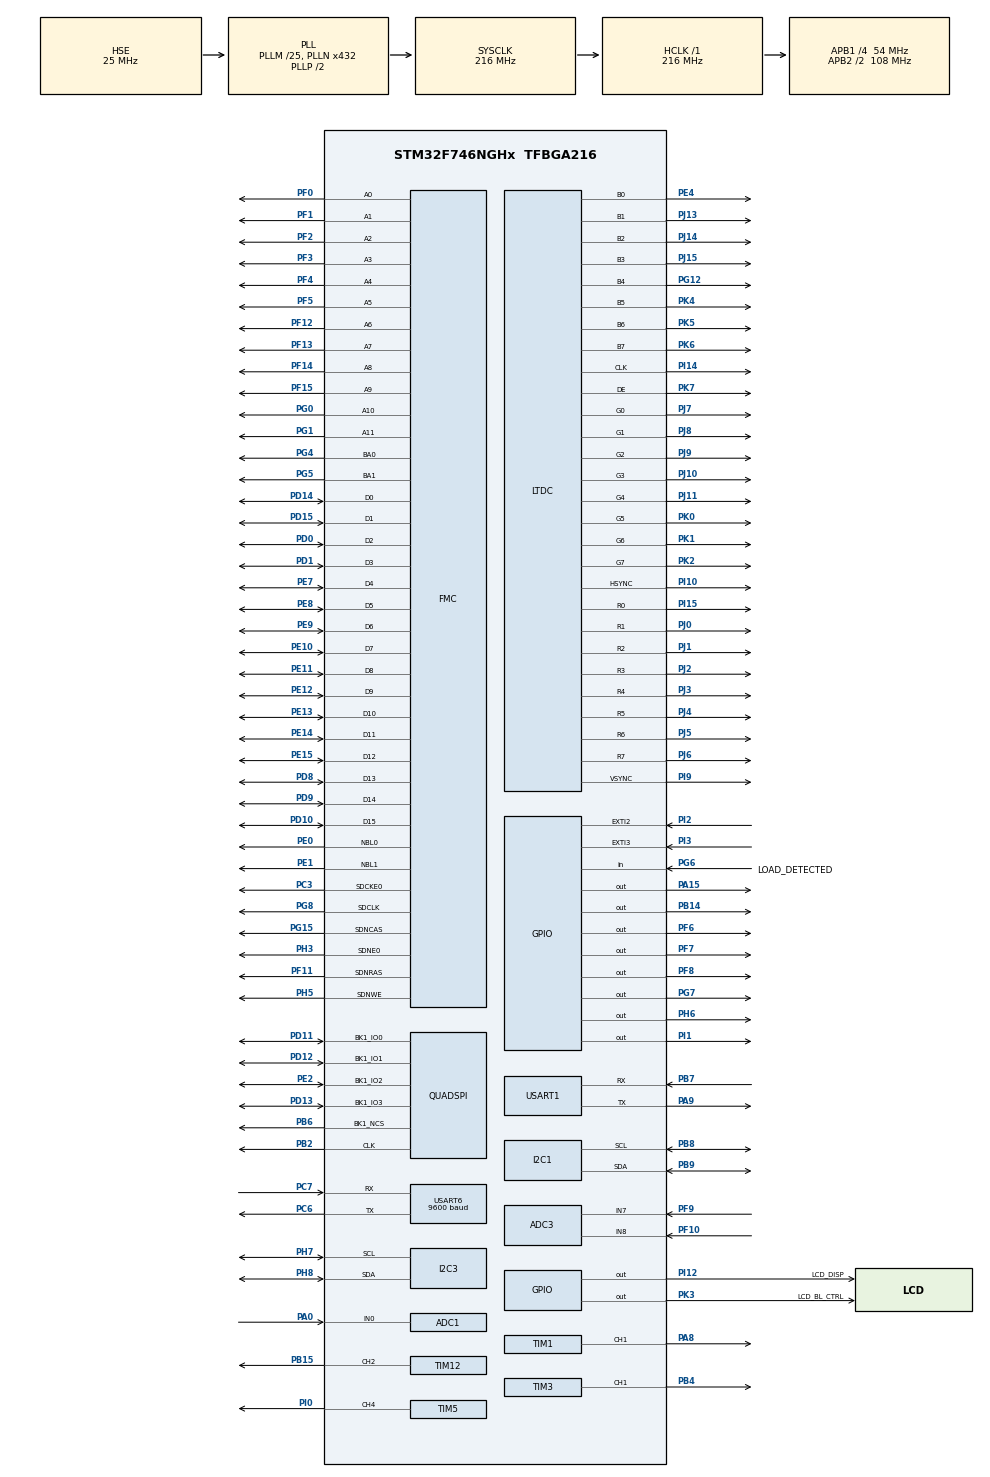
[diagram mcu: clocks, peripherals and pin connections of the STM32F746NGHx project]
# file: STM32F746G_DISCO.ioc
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ADC1.Channel-0\#ChannelRegularConversion=ADC_CHANNEL_0
ADC1.NbrOfConversionFlag=1
ADC1.Rank-0\#ChannelRegularConversion=1
ADC1.SamplingTime-0\#ChannelRegularConversion=ADC_SAMPLETIME_480CYCLES
ADC1.master=1
ADC3.Channel-0\#ChannelRegularConversion=ADC_CHANNEL_8
ADC3.NbrOfConversionFlag=1
ADC3.Rank-0\#ChannelRegularConversion=1
ADC3.SamplingTime-0\#ChannelRegularConversion=ADC_SAMPLETIME_480CYCLES
CORTEX_M7.ART_ACCLERATOR_ENABLE=1
CORTEX_M7.AccessPermission-Cortex_Memory_Protection_Unit_Region0_Settings=MPU_REGION_FULL_ACCESS
CORTEX_M7.AccessPermission-Cortex_Memory_Protection_Unit_Region1_Settings=MPU_REGION_FULL_ACCESS
CORTEX_M7.BaseAddress-Cortex_Memory_Protection_Unit_Region0_Settings=0x90000000
CORTEX_M7.BaseAddress-Cortex_Memory_Protection_Unit_Region1_Settings=0x90000000
CORTEX_M7.CPU_DCache=Enabled
CORTEX_M7.CPU_ICache=Enabled
CORTEX_M7.Enable-Cortex_Memory_Protection_Unit_Region0_Settings=MPU_REGION_ENABLE
CORTEX_M7.Enable-Cortex_Memory_Protection_Unit_Region1_Settings=MPU_REGION_ENABLE
CORTEX_M7.IsCacheable-Cortex_Memory_Protection_Unit_Region1_Settings=MPU_ACCESS_CACHEABLE
CORTEX_M7.MPU_Control=MPU_PRIVILEGED_DEFAULT
CORTEX_M7.PREFETCH_ENABLE=1
CORTEX_M7.Size-Cortex_Memory_Protection_Unit_Region0_Settings=MPU_REGION_SIZE_256MB
CORTEX_M7.Size-Cortex_Memory_Protection_Unit_Region1_Settings=MPU_REGION_SIZE_16MB
FMC.CASLatency1=FMC_SDRAM_CAS_LATENCY_3
FMC.ExitSelfRefreshDelay1=7
FMC.LoadToActiveDelay1=2
FMC.RCDDelay1=2
FMC.RPDelay1=2
FMC.ReadBurst1=FMC_SDRAM_RBURST_ENABLE
FMC.RowCycleDelay1=7
FMC.SDClockPeriod1=FMC_SDRAM_CLOCK_PERIOD_2
FMC.SelfRefreshTime1=4
FMC.WriteRecoveryTime1=3
FREERTOS.Tasks01=defaultTask,40,128,StartDefaultTask,Default,NULL,Dynamic,NULL,NULL;TouchGFXTask,24,4096,TouchGFX_Task,As external,NULL,Dynamic,NULL,NULL;videoTask,8,1000,videoTaskFunc,As external,NULL,Dynamic,NULL,NULL
FREERTOS.configTOTAL_HEAP_SIZE=75000
FREERTOS.configUSE_APPLICATION_TASK_TAG=1
FREERTOS.configUSE_IDLE_HOOK=1
I2C1.I2C_Coeff_DF=15
I2C1.Timing=0x00D0F4FF
I2C3.Timing=0x20404768
LIBJPEG.RGB_ORDERING=BGR
LTDC.ActiveH=272
LTDC.ActiveW=480
LTDC.Alpha_L0=255
LTDC.FBStartAdress_L0=0xC0000000
LTDC.HBP=13
LTDC.HFP=32
LTDC.HSync=41
LTDC.ImageHeight_L0=272
LTDC.ImageWidth_L0=480
LTDC.Layers=0
LTDC.PixelFormat_L0=LTDC_PIXEL_FORMAT_RGB565
LTDC.VSync=10
LTDC.WindowX1_L0=480
LTDC.WindowY1_L0=272
Mcu.Family=STM32F7
Mcu.Name=STM32F746NGHx
Mcu.Package=TFBGA216
NVIC.DMA2D_IRQn=true\:5\:0\:true\:false\:true\:true\:true\:true\:true
NVIC.EXTI2_IRQn=true\:5\:0\:false\:false\:true\:true\:true\:true\:true
NVIC.EXTI3_IRQn=true\:5\:0\:false\:false\:true\:true\:true\:true\:true
NVIC.LTDC_IRQn=true\:5\:0\:true\:false\:true\:true\:true\:true\:true
NVIC.PriorityGroup=NVIC_PRIORITYGROUP_4
NVIC.TIM6_DAC_IRQn=true\:0\:0\:false\:false\:true\:false\:false\:true\:true
NVIC.TimeBase=TIM6_DAC_IRQn
NVIC.TimeBaseIP=TIM6
NVIC.USART1_IRQn=true\:5\:0\:false\:false\:true\:true\:true\:true\:true
NVIC.USART6_IRQn=true\:5\:0\:false\:false\:true\:true\:true\:true\:true
PA0/WKUP.Signal=ADCx_IN0
PA13.Mode=Serial_Wire
PA13.Signal=SYS_JTMS-SWDIO
PA14.Mode=Serial_Wire
PA14.Signal=SYS_JTCK-SWCLK
PA15.Signal=GPIO_Output
PA8.Signal=S_TIM1_CH1
PA9.Mode=Asynchronous
PA9.Signal=USART1_TX
PB14.Signal=GPIO_Output
PB15.Signal=S_TIM12_CH2
PB2.Mode=Single Bank 1
PB2.Signal=QUADSPI_CLK
PB4.Signal=S_TIM3_CH1
PB6.Mode=Single Bank 1
PB6.Signal=QUADSPI_BK1_NCS
PB7.Mode=Asynchronous
PB7.Signal=USART1_RX
PB8.Mode=I2C
PB8.Signal=I2C1_SCL
PB9.Mode=I2C
PB9.Signal=I2C1_SDA
PC3.Mode=SdramChipSelect1_1
PC3.Signal=FMC_SDCKE0
PC6.Mode=Asynchronous
PC6.Signal=USART6_TX
PC7.Mode=Asynchronous
PC7.Signal=USART6_RX
PD0.Signal=FMC_D2_DA2
PD1.Signal=FMC_D3_DA3
PD10.Signal=FMC_D15_DA15
PD11.Mode=Single Bank 1
PD11.Signal=QUADSPI_BK1_IO0
PD12.Mode=Single Bank 1
PD12.Signal=QUADSPI_BK1_IO1
PD13.Mode=Single Bank 1
PD13.Signal=QUADSPI_BK1_IO3
PD14.Signal=FMC_D0_DA0
PD15.Signal=FMC_D1_DA1
PD8.Signal=FMC_D13_DA13
PD9.Signal=FMC_D14_DA14
PE0.Signal=FMC_NBL0
PE1.Signal=FMC_NBL1
PE10.Signal=FMC_D7_DA7
PE11.Signal=FMC_D8_DA8
PE12.Signal=FMC_D9_DA9
PE13.Signal=FMC_D10_DA10
PE14.Signal=FMC_D11_DA11
PE15.Signal=FMC_D12_DA12
PE2.Mode=Single Bank 1
PE2.Signal=QUADSPI_BK1_IO2
PE4.Mode=RGB888
PE4.Signal=LTDC_B0
PE7.Signal=FMC_D4_DA4
PE8.Signal=FMC_D5_DA5
PE9.Signal=FMC_D6_DA6
PF0.Signal=FMC_A0
PF1.Signal=FMC_A1
PF10.Mode=IN8
PF10.Signal=ADC3_IN8
PF11.Signal=FMC_SDNRAS
PF12.Signal=FMC_A6
PF13.Signal=FMC_A7
PF14.Signal=FMC_A8
PF15.Signal=FMC_A9
PF2.Signal=FMC_A2
PF3.Signal=FMC_A3
PF4.Signal=FMC_A4
PF5.Signal=FMC_A5
PF6.Signal=GPIO_Output
PF7.Signal=GPIO_Output
PF8.Signal=GPIO_Output
PF9.Mode=IN7
PF9.Signal=ADC3_IN7
PG0.Signal=FMC_A10
PG1.Signal=FMC_A11
PG12.Mode=RGB888
PG12.Signal=LTDC_B4
PG15.Signal=FMC_SDNCAS
PG4.Signal=FMC_A14_BA0
PG5.Signal=FMC_A15_BA1
PG6.GPIO_Label=LOAD_DETECTED
PG6.GPIO_PuPd=GPIO_PULLUP
PG6.Signal=GPIO_Input
PG7.Signal=GPIO_Output
PG8.Signal=FMC_SDCLK
PH0/OSC_IN.Mode=HSE-External-Oscillator
PH0/OSC_IN.Signal=RCC_OSC_IN
PH1/OSC_OUT.Mode=HSE-External-Oscillator
PH1/OSC_OUT.Signal=RCC_OSC_OUT
PH3.Mode=SdramChipSelect1_1
PH3.Signal=FMC_SDNE0
PH5.Signal=FMC_SDNWE
PH6.Signal=GPIO_Output
PH7.GPIO_Pu=GPIO_PULLUP
PH7.Mode=I2C
PH7.Signal=I2C3_SCL
PH8.GPIO_Pu=GPIO_PULLUP
PH8.Mode=I2C
PH8.Signal=I2C3_SDA
PI0.Signal=S_TIM5_CH4
PI1.Signal=GPIO_Output
PI10.Mode=RGB888
PI10.Signal=LTDC_HSYNC
PI12.GPIO_Label=LCD_DISP
PI12.PinState=GPIO_PIN_SET
PI12.Signal=GPIO_Output
PI14.Mode=RGB888
PI14.Signal=LTDC_CLK
PI15.Mode=RGB888
PI15.Signal=LTDC_R0
PI2.GPIO_PuPd=GPIO_PULLUP
PI2.Signal=GPXTI2
PI3.GPIO_PuPd=GPIO_PULLUP
PI3.Signal=GPXTI3
PI9.Mode=RGB888
PI9.Signal=LTDC_VSYNC
PJ0.Mode=RGB888
PJ0.Signal=LTDC_R1
PJ1.Mode=RGB888
PJ1.Signal=LTDC_R2
PJ10.Mode=RGB888
PJ10.Signal=LTDC_G3
PJ11.Mode=RGB888
PJ11.Signal=LTDC_G4
PJ13.Mode=RGB888
PJ13.Signal=LTDC_B1
PJ14.Mode=RGB888
PJ14.Signal=LTDC_B2
PJ15.Mode=RGB888
PJ15.Signal=LTDC_B3
PJ2.Mode=RGB888
PJ2.Signal=LTDC_R3
PJ3.Mode=RGB888
PJ3.Signal=LTDC_R4
PJ4.Mode=RGB888
PJ4.Signal=LTDC_R5
PJ5.Mode=RGB888
PJ5.Signal=LTDC_R6
PJ6.Mode=RGB888
PJ6.Signal=LTDC_R7
PJ7.Mode=RGB888
PJ7.Signal=LTDC_G0
PJ8.Mode=RGB888
PJ8.Signal=LTDC_G1
PJ9.Mode=RGB888
PJ9.Signal=LTDC_G2
PK0.Mode=RGB888
PK0.Signal=LTDC_G5
PK1.Mode=RGB888
PK1.Signal=LTDC_G6
PK2.Mode=RGB888
PK2.Signal=LTDC_G7
PK3.GPIO_Label=LCD_BL_CTRL
PK3.PinState=GPIO_PIN_SET
PK3.Signal=GPIO_Output
PK4.Mode=RGB888
PK4.Signal=LTDC_B5
PK5.Mode=RGB888
PK5.Signal=LTDC_B6
PK6.Mode=RGB888
PK6.Signal=LTDC_B7
PK7.Mode=RGB888
PK7.Signal=LTDC_DE
ProjectManager.HeapSize=0xA00
ProjectManager.StackSize=0xA00
ProjectManager.TargetToolchain=STM32CubeIDE
QUADSPI.ChipSelectHighTime=QSPI_CS_HIGH_TIME_6_CYCLE
QUADSPI.ClockPrescaler=1
QUADSPI.FifoThreshold=4
QUADSPI.FlashSize=24
QUADSPI.SampleShifting=QSPI_SAMPLE_SHIFTING_HALFCYCLE
RCC.AHBFreq_Value=216000000
RCC.APB1CLKDivider=RCC_HCLK_DIV4
RCC.APB1Freq_Value=54000000
RCC.APB1TimFreq_Value=108000000
RCC.APB2CLKDivider=RCC_HCLK_DIV2
RCC.APB2Freq_Value=108000000
RCC.APB2TimFreq_Value=216000000
RCC.CortexFreq_Value=216000000
RCC.HCLKFreq_Value=216000000
RCC.HSE_VALUE=25000000
RCC.HSI_VALUE=16000000
RCC.LSE_VALUE=32768
RCC.PLLI2SN=100
RCC.PLLM=25
RCC.PLLN=432
RCC.PLLSAIN=384
RCC.PLLSAIR=5
RCC.PLLSAIRDiv=RCC_PLLSAIDIVR_8
RCC.PLLSourceVirtual=RCC_PLLSOURCE_HSE
RCC.SYSCLKFreq_VALUE=216000000
RCC.SYSCLKSource=RCC_SYSCLKSOURCE_PLLCLK
RCC.USBFreq_Value=216000000
RCC.VCOOutputFreq_Value=432000000
SH.ADCx_IN0.0=ADC1_IN0,IN0
SH.FMC_A0.0=FMC_A0,12b-sda1
SH.FMC_A1.0=FMC_A1,12b-sda1
SH.FMC_A10.0=FMC_A10,12b-sda1
SH.FMC_A11.0=FMC_A11,12b-sda1
SH.FMC_A14_BA0.0=FMC_BA0,FourSdramBanks1
SH.FMC_A15_BA1.0=FMC_BA1,FourSdramBanks1
SH.FMC_A2.0=FMC_A2,12b-sda1
SH.FMC_A3.0=FMC_A3,12b-sda1
SH.FMC_A4.0=FMC_A4,12b-sda1
SH.FMC_A5.0=FMC_A5,12b-sda1
SH.FMC_A6.0=FMC_A6,12b-sda1
SH.FMC_A7.0=FMC_A7,12b-sda1
SH.FMC_A8.0=FMC_A8,12b-sda1
SH.FMC_A9.0=FMC_A9,12b-sda1
SH.FMC_D0_DA0.0=FMC_D0,sd-16b-d1
SH.FMC_D10_DA10.0=FMC_D10,sd-16b-d1
SH.FMC_D11_DA11.0=FMC_D11,sd-16b-d1
SH.FMC_D12_DA12.0=FMC_D12,sd-16b-d1
SH.FMC_D13_DA13.0=FMC_D13,sd-16b-d1
SH.FMC_D14_DA14.0=FMC_D14,sd-16b-d1
SH.FMC_D15_DA15.0=FMC_D15,sd-16b-d1
SH.FMC_D1_DA1.0=FMC_D1,sd-16b-d1
SH.FMC_D2_DA2.0=FMC_D2,sd-16b-d1
SH.FMC_D3_DA3.0=FMC_D3,sd-16b-d1
SH.FMC_D4_DA4.0=FMC_D4,sd-16b-d1
SH.FMC_D5_DA5.0=FMC_D5,sd-16b-d1
SH.FMC_D6_DA6.0=FMC_D6,sd-16b-d1
SH.FMC_D7_DA7.0=FMC_D7,sd-16b-d1
SH.FMC_D8_DA8.0=FMC_D8,sd-16b-d1
SH.FMC_D9_DA9.0=FMC_D9,sd-16b-d1
SH.FMC_NBL0.0=FMC_NBL0,Sd2ByteEnable1
SH.FMC_NBL1.0=FMC_NBL1,Sd2ByteEnable1
SH.FMC_SDCLK.0=FMC_SDCLK,12b-sda1
SH.FMC_SDNCAS.0=FMC_SDNCAS,12b-sda1
SH.FMC_SDNRAS.0=FMC_SDNRAS,12b-sda1
SH.FMC_SDNWE.0=FMC_SDNWE,12b-sda1
SH.S_TIM12_CH2.0=TIM12_CH2,PWM Generation2 CH2
SH.S_TIM1_CH1.0=TIM1_CH1,PWM Generation1 CH1
SH.S_TIM3_CH1.0=TIM3_CH1,PWM Generation1 CH1
SH.S_TIM5_CH4.0=TIM5_CH4,PWM Generation4 CH4
STMicroelectronics.X-CUBE-TOUCHGFX.4.26.1.ApplicationCcGraphicsJjApplication=TouchGFXOoGenerator
STMicroelectronics.X-CUBE-TOUCHGFX.4.26.1.tgfx_address1=0xC0000000
STMicroelectronics.X-CUBE-TOUCHGFX.4.26.1.tgfx_address2=0xC003FC00
STMicroelectronics.X-CUBE-TOUCHGFX.4.26.1.tgfx_buffering_strategy=Double
STMicroelectronics.X-CUBE-TOUCHGFX.4.26.1.tgfx_display_interface=disp_ltdc
STMicroelectronics.X-CUBE-TOUCHGFX.4.26.1.tgfx_hardware_accelerator=dma_2d
STMicroelectronics.X-CUBE-TOUCHGFX.4.26.1.tgfx_location=Allocate
STMicroelectronics.X-CUBE-TOUCHGFX.4.26.1.tgfx_vector_fonts=Enabled
STMicroelectronics.X-CUBE-TOUCHGFX.4.26.1.tgfx_vector_rendering=Software
STMicroelectronics.X-CUBE-TOUCHGFX.4.26.1.tgfx_video=Software
STMicroelectronics.X-CUBE-TOUCHGFX.4.26.1.tgfx_video_buffer_format=RGB565\:2
STMicroelectronics.X-CUBE-TOUCHGFX.4.26.1.tgfx_video_height=272
STMicroelectronics.X-CUBE-TOUCHGFX.4.26.1.tgfx_video_strategy=2
STMicroelectronics.X-CUBE-TOUCHGFX.4.26.1.tgfx_video_width=480
STMicroelectronics.X-CUBE-TOUCHGFX.4.26.1.tgfx_vsync=vsync_ltdc
TIM1.Channel-PWM\ Generation1\ CH1=TIM_CHANNEL_1
TIM1.Period=255
TIM1.Prescaler=39
TIM12.Channel-PWM\ Generation2\ CH2=TIM_CHANNEL_2
TIM12.Period=255
TIM12.Prescaler=19
TIM2.Prescaler=107
TIM3.Channel-PWM\ Generation1\ CH1=TIM_CHANNEL_1
TIM3.Period=255
TIM3.Prescaler=19
TIM5.Channel-PWM\ Generation4\ CH4=TIM_CHANNEL_4
TIM5.Period=255
TIM5.Prescaler=19
USART1.VirtualMode-Asynchronous=VM_ASYNC
USART6.BaudRate=9600
USART6.VirtualMode-Asynchronous=VM_ASYNC
VP_CRC_VS_CRC.Mode=CRC_Activate
VP_DMA2D_VS_DMA2D.Mode=DMA2D_Activate
VP_FREERTOS_VS_CMSIS_V2.Mode=CMSIS_V2
VP_LIBJPEG_VS_JPEGLIB.Mode=Enabled
VP_STMicroelectronics.X-CUBE-TOUCHGFX_VS_GraphicsJjApplication_4.26.1.Mode=GraphicsJjApplication
VP_SYS_VS_tim6.Mode=TIM6
VP_TIM12_VS_ClockSourceINT.Mode=Internal
VP_TIM13_VS_ClockSourceINT.Mode=Enable_Timer
VP_TIM1_VS_ClockSourceINT.Mode=Internal
VP_TIM2_VS_ClockSourceINT.Mode=Internal
VP_TIM3_VS_ClockSourceINT.Mode=Internal
VP_TIM5_VS_ClockSourceINT.Mode=Internal
VP_TIM8_VS_ClockSourceINT.Mode=Internal
board=custom

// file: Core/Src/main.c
/* USER CODE BEGIN Header */
/**
  ******************************************************************************
  * @file           : main.c
  * @brief          : Main program body
  ******************************************************************************
  * @attention
  *
  * <h2><center>&copy; Copyright (c) 2020 STMicroelectronics.
  * All rights reserved.</center></h2>
  *
  * This software component is licensed by ST under Ultimate Liberty license
  * SLA0044, the "License"; You may not use this file except in compliance with
  * the License. You may obtain a copy of the License at:
  *                             www.st.com/SLA0044
  *
  ******************************************************************************
  */
/* USER CODE END Header */
#include "main.h"
#include "cmsis_os.h"
#include "libjpeg.h"
#include "app_touchgfx.h"

/* USER CODE BEGIN Includes */
#include "motor_control.h"
#include "uart_protokol.h"
#include "uartcom.h"
#include "lift_lineer.h"
#include "egim_lineer.h"
#include "buzzer_control.h"
#include "mpu9250.h"     /* IMU Sürücüsü */
#include "imu_fusion.h"  /* Sensör Füzyonu */
#include <math.h>
#include "acs712.h" // Akım Sensörü Kütüphanesi
#include "battery.h"
//#include "aht10.h"

/* USER CODE END Includes */

/* USER CODE BEGIN PD */

#define REFRESH_COUNT        1835

#define SDRAM_TIMEOUT                            ((uint32_t)0xFFFF)
#define SDRAM_MODEREG_BURST_LENGTH_1             ((uint16_t)0x0000)
#define SDRAM_MODEREG_BURST_LENGTH_2             ((uint16_t)0x0001)
#define SDRAM_MODEREG_BURST_LENGTH_4             ((uint16_t)0x0002)
#define SDRAM_MODEREG_BURST_LENGTH_8             ((uint16_t)0x0004)
#define SDRAM_MODEREG_BURST_TYPE_SEQUENTIAL      ((uint16_t)0x0000)
#define SDRAM_MODEREG_BURST_TYPE_INTERLEAVED     ((uint16_t)0x0008)
#define SDRAM_MODEREG_CAS_LATENCY_2              ((uint16_t)0x0020)
#define SDRAM_MODEREG_CAS_LATENCY_3              ((uint16_t)0x0030)
#define SDRAM_MODEREG_OPERATING_MODE_STANDARD    ((uint16_t)0x0000)
#define SDRAM_MODEREG_WRITEBURST_MODE_PROGRAMMED ((uint16_t)0x0000)
#define SDRAM_MODEREG_WRITEBURST_MODE_SINGLE     ((uint16_t)0x0200)

#define FLASH_READ_JEDEC_ID				0x9F
#define FLASH_FAST_READ_QUAD_IO		 	0xEB
#define FLASH_REVC03_MANUFACTURER_ID	0xEF
#define FLASH_N25Q128A_DUMMY_CYCLES		0x0A
#define FLASH_W25Q128J_DUMMY_CYCLES		0x06

/* USER CODE END PD */

ADC_HandleTypeDef hadc1;
ADC_HandleTypeDef hadc3;

CRC_HandleTypeDef hcrc;

DMA2D_HandleTypeDef hdma2d;

I2C_HandleTypeDef hi2c1;
I2C_HandleTypeDef hi2c3;

LTDC_HandleTypeDef hltdc;

QSPI_HandleTypeDef hqspi;

TIM_HandleTypeDef htim1;
TIM_HandleTypeDef htim2;
TIM_HandleTypeDef htim3;
TIM_HandleTypeDef htim5;
TIM_HandleTypeDef htim8;
TIM_HandleTypeDef htim12;
TIM_HandleTypeDef htim13;

UART_HandleTypeDef huart1;
UART_HandleTypeDef huart6;

SDRAM_HandleTypeDef hsdram1;

/* Definitions for defaultTask */
osThreadId_t defaultTaskHandle;
const osThreadAttr_t defaultTask_attributes = {
  .name = "defaultTask",
  .stack_size = 128 * 4,
  .priority = (osPriority_t) osPriorityHigh,
};
/* Definitions for TouchGFXTask */
osThreadId_t TouchGFXTaskHandle;
const osThreadAttr_t TouchGFXTask_attributes = {
  .name = "TouchGFXTask",
  .stack_size = 4096 * 4,
  .priority = (osPriority_t) osPriorityNormal,
};
/* Definitions for videoTask */
osThreadId_t videoTaskHandle;
const osThreadAttr_t videoTask_attributes = {
  .name = "videoTask",
  .stack_size = 1000 * 4,
  .priority = (osPriority_t) osPriorityLow,
};
/* USER CODE BEGIN PV */

volatile float aku_voltaji = 0.0f;

// akım sensoru sabiti
volatile float g_forklift_akim = 0.0f;

/* Definitions for imuTask */
osThreadId_t imuTaskHandle;
const osThreadAttr_t imuTask_attributes = {
  .name = "imuTask",
  .stack_size = 256 * 4,
  .priority = (osPriority_t) osPriorityAboveNormal,
};

/* Definitions for aht10Task */
/*osThreadId_t aht10TaskHandle;
const osThreadAttr_t aht10Task_attributes = {
  .name = "aht10Task",
  .stack_size = 256 * 4, // Güvenli ve yeterli stack boyutu
  .priority = (osPriority_t) osPriorityLow, // Düşük öncelik (motorları asla ezmez)
};*/

/* Definitions for protocolTask (uart_protokol.c - Orange Pi binary protokolu) */
osThreadId_t protocolTaskHandle;
const osThreadAttr_t protocolTask_attributes = {
  .name = "protocolTask",
  .stack_size = 512 * 4,
  .priority = (osPriority_t) osPriorityHigh,
};

osThreadId_t batteryTaskHandle;
const osThreadAttr_t batteryTask_attributes = {
  .name = "batteryTask",
  .stack_size = 256 * 4, /* Batarya hesaplaması ve FreeRTOS için güvenli bellek alanı */
  .priority = (osPriority_t) osPriorityLow, /* Motor ve haberleşme görevlerini engellememesi için düşük öncelik */
};

static FMC_SDRAM_CommandTypeDef Command;

// Bluetooth'tan (HC-06 / USART6) gelen hedefler:
volatile int16_t left_target = 0;
volatile int16_t right_target = 0;

// Orange Pi'den (USART1 binary protokol) gelen hedefler:
volatile float opi_left_target = 0.0f;
volatile float opi_right_target = 0.0f;
static volatile bool soft_estop_latched = false;

/* Fiziksel mod anahtari eklenene kadar Bluetooth komutu zaman asimina ugrar. */
#define MANUAL_COMMAND_TIMEOUT_MS 500U
static volatile uint32_t manual_last_command_tick = 0U;

// Orange Pi binary protokolu
ProtocolHandler_t g_protocol;
uint8_t rx_byte_dma;
/* 0: Bu surumde fiziksel ADC donusumu henuz kalibre edilmedi/bilinmiyor. */
volatile int battery_mv = 0;

/* Fork (lift) guvenlik zaman asimi takibi */
static uint32_t fork_action_start_tick = 0U;
static uint16_t fork_active_timeout_ms = 0U;
static bool     fork_timeout_active = false;

MPU9250_HandleTypeDef hmpu1;
IMU_Fusion_t          imu_fusion;
bool                  imu_is_ready = false;
volatile float g_shared_imu_yaw = NAN;

extern bool g_is_autonomous_mode;
/*AHT10_HandleTypedef aht10_sensor;
volatile float g_aht10_temperature = 0.0f;
volatile float g_aht10_humidity = 0.0f;
volatile bool  g_aht10_is_ready = false;*/

/* USER CODE END PV */

void SystemClock_Config(void);
static void MPU_Config(void);
static void MX_GPIO_Init(void);
static void MX_CRC_Init(void);
static void MX_DMA2D_Init(void);
static void MX_FMC_Init(void);
static void MX_I2C3_Init(void);
static void MX_LTDC_Init(void);
static void MX_QUADSPI_Init(void);
static void MX_ADC3_Init(void);
static void MX_I2C1_Init(void);
static void MX_TIM1_Init(void);
static void MX_TIM2_Init(void);
static void MX_TIM3_Init(void);
static void MX_TIM5_Init(void);
static void MX_TIM8_Init(void);
static void MX_TIM12_Init(void);
static void MX_TIM13_Init(void);
static void MX_USART1_UART_Init(void);
static void MX_USART6_UART_Init(void);
static void MX_ADC1_Init(void);
void StartDefaultTask(void *argument);
extern void TouchGFX_Task(void *argument);
extern void videoTaskFunc(void *argument);

/* USER CODE BEGIN PFP */
void GetManufacturerId (uint8_t *manufacturer_id);
void EnableMemoryMappedMode(uint8_t manufacturer_id);
void StartImuTask(void *argument);
void StartProtocolTask(void *argument);
void StartBatteryTask(void *argument);
//void StartAht10Task(void *argument);

/* USER CODE END PFP */

int main(void)
{

  /* MPU Configuration--------------------------------------------------------*/
  MPU_Config();

  /* Enable the CPU Cache */

  /* Enable I-Cache---------------------------------------------------------*/
  SCB_EnableICache();

  /* Enable D-Cache---------------------------------------------------------*/
  SCB_EnableDCache();

  /* MCU Configuration--------------------------------------------------------*/

  /* Reset of all peripherals, Initializes the Flash interface and the Systick. */
  HAL_Init();

  /* Configure the system clock */
  SystemClock_Config();

  /* Initialize all configured peripherals */
  MX_GPIO_Init();
  MX_CRC_Init();
  MX_DMA2D_Init();
  MX_FMC_Init();
  MX_I2C3_Init();
  MX_LTDC_Init();
  MX_QUADSPI_Init();
  MX_LIBJPEG_Init();
  MX_ADC3_Init();
  MX_I2C1_Init();
  MX_TIM1_Init();
  MX_TIM2_Init();
  MX_TIM3_Init();
  MX_TIM5_Init();
  MX_TIM8_Init();
  MX_TIM12_Init();
  MX_TIM13_Init();
  MX_USART1_UART_Init();
  MX_USART6_UART_Init();
  MX_ADC1_Init();
  MX_TouchGFX_Init();
  /* Call PreOsInit function */
  MX_TouchGFX_PreOSInit();
  /* USER CODE BEGIN 2 */
  HAL_Delay(3000U);
  MotorControl_Init();
  LiftLineer_Init();
  EgimLineer_Init();
  BuzzerControl_Init();

  /* IMU dt hesabi icin Cortex-M7 cycle counter'ini ac. */
  CoreDebug->DEMCR |= CoreDebug_DEMCR_TRCENA_Msk;
  DWT->CYCCNT = 0U;
  DWT->CTRL |= DWT_CTRL_CYCCNTENA_Msk;

  UartCom_BluetoothInit(&huart6); // Bluetooth (USART6) - manuel kontrol

  Protocol_Init(&g_protocol, &huart1); // Orange Pi binary protokolu (USART1)
  g_protocol.odometry_tx_mode = TX_MODE_ON_REQUEST;
  g_protocol.status_tx_mode = TX_MODE_ON_REQUEST;

  /* IMU (MPU9250) Başlatma ve Kalibrasyon */
    Fusion_Init(&imu_fusion);
    if (MPU9250_Init(&hmpu1, &hi2c1, ACCEL_FS_4G, GYRO_FS_500DPS) == HAL_OK)
    {
        /* Araç sabit dururken gyro bias kalibrasyonu (100 örnek) */
        if (Fusion_CalibrateGyroBias(&imu_fusion, &hmpu1, 300) == HAL_OK)
        {
            imu_is_ready = true;
        }
    }

    /* AHT10 Başlatma */
        /*aht10_sensor.hi2c = &hi2c1; // I2C portunu yapıya bağlıyoruz
        if (AHT10_Init(&aht10_sensor) == HAL_OK) {
            g_aht10_is_ready = 1;   // Sensör hazır bayrağını kaldırıyoruz
        } else {
            g_aht10_is_ready = 0;
        }*/

  // USART1 (Orange Pi) UART RX kesmesini baslat
  HAL_UART_Receive_IT(&huart1, &rx_byte_dma, 1);
  /* USER CODE END 2 */

  /* Init scheduler */
  osKernelInitialize();

  /* Create the thread(s) */
  /* creation of defaultTask */
  defaultTaskHandle = osThreadNew(StartDefaultTask, NULL, &defaultTask_attributes);

  /* creation of TouchGFXTask */
  TouchGFXTaskHandle = osThreadNew(TouchGFX_Task, NULL, &TouchGFXTask_attributes);

  /* creation of videoTask */
  videoTaskHandle = osThreadNew(videoTaskFunc, NULL, &videoTask_attributes);

  /* USER CODE BEGIN RTOS_THREADS */
  /* add threads, ... */
  imuTaskHandle = osThreadNew(StartImuTask, NULL, &imuTask_attributes);
  //aht10TaskHandle = osThreadNew(StartAht10Task, NULL, &aht10Task_attributes);
  protocolTaskHandle = osThreadNew(StartProtocolTask, NULL, &protocolTask_attributes);
  batteryTaskHandle = osThreadNew(StartBatteryTask, NULL, &batteryTask_attributes);

  /* USER CODE END RTOS_THREADS */

  /* Start scheduler */
  osKernelStart();

  /* We should never get here as control is now taken by the scheduler */

  /* Infinite loop */
  while (1)
  {

  }
}

void SystemClock_Config(void)
{
  RCC_OscInitTypeDef RCC_OscInitStruct = {0};
  RCC_ClkInitTypeDef RCC_ClkInitStruct = {0};

  /** Configure the main internal regulator output voltage
  */
  __HAL_RCC_PWR_CLK_ENABLE();
  __HAL_PWR_VOLTAGESCALING_CONFIG(PWR_REGULATOR_VOLTAGE_SCALE1);

  /** Initializes the RCC Oscillators according to the specified parameters
  * in the RCC_OscInitTypeDef structure.
  */
  RCC_OscInitStruct.OscillatorType = RCC_OSCILLATORTYPE_HSE;
  RCC_OscInitStruct.HSEState = RCC_HSE_ON;
  RCC_OscInitStruct.PLL.PLLState = RCC_PLL_ON;
  RCC_OscInitStruct.PLL.PLLSource = RCC_PLLSOURCE_HSE;
  RCC_OscInitStruct.PLL.PLLM = 25;
  RCC_OscInitStruct.PLL.PLLN = 432;
  RCC_OscInitStruct.PLL.PLLP = RCC_PLLP_DIV2;
  RCC_OscInitStruct.PLL.PLLQ = 2;
  if (HAL_RCC_OscConfig(&RCC_OscInitStruct) != HAL_OK)
  {
    Error_Handler();
  }

  /** Activate the Over-Drive mode
  */
  if (HAL_PWREx_EnableOverDrive() != HAL_OK)
  {
    Error_Handler();
  }

  /** Initializes the CPU, AHB and APB buses clocks
  */
  RCC_ClkInitStruct.ClockType = RCC_CLOCKTYPE_HCLK|RCC_CLOCKTYPE_SYSCLK
                              |RCC_CLOCKTYPE_PCLK1|RCC_CLOCKTYPE_PCLK2;
  RCC_ClkInitStruct.SYSCLKSource = RCC_SYSCLKSOURCE_PLLCLK;
  RCC_ClkInitStruct.AHBCLKDivider = RCC_SYSCLK_DIV1;
  RCC_ClkInitStruct.APB1CLKDivider = RCC_HCLK_DIV4;
  RCC_ClkInitStruct.APB2CLKDivider = RCC_HCLK_DIV2;

  if (HAL_RCC_ClockConfig(&RCC_ClkInitStruct, FLASH_LATENCY_7) != HAL_OK)
  {
    Error_Handler();
  }
}

static void MX_ADC1_Init(void)
{

  ADC_ChannelConfTypeDef sConfig = {0};

  /** Configure the global features of the ADC (Clock, Resolution, Data Alignment and number of conversion)
  */
  hadc1.Instance = ADC1;
  hadc1.Init.ClockPrescaler = ADC_CLOCK_SYNC_PCLK_DIV4;
  hadc1.Init.Resolution = ADC_RESOLUTION_12B;
  hadc1.Init.ScanConvMode = ADC_SCAN_DISABLE;
  hadc1.Init.ContinuousConvMode = DISABLE;
  hadc1.Init.DiscontinuousConvMode = DISABLE;
  hadc1.Init.ExternalTrigConvEdge = ADC_EXTERNALTRIGCONVEDGE_NONE;
  hadc1.Init.ExternalTrigConv = ADC_SOFTWARE_START;
  hadc1.Init.DataAlign = ADC_DATAALIGN_RIGHT;
  hadc1.Init.NbrOfConversion = 1;
  hadc1.Init.DMAContinuousRequests = DISABLE;
  hadc1.Init.EOCSelection = ADC_EOC_SINGLE_CONV;
  if (HAL_ADC_Init(&hadc1) != HAL_OK)
  {
    Error_Handler();
  }

  /** Configure for the selected ADC regular channel its corresponding rank in the sequencer and its sample time.
  */
  sConfig.Channel = ADC_CHANNEL_0;
  sConfig.Rank = ADC_REGULAR_RANK_1;
  sConfig.SamplingTime = ADC_SAMPLETIME_480CYCLES;
  if (HAL_ADC_ConfigChannel(&hadc1, &sConfig) != HAL_OK)
  {
    Error_Handler();
  }

}

static void MX_ADC3_Init(void)
{

  ADC_ChannelConfTypeDef sConfig = {0};

  /** Configure the global features of the ADC (Clock, Resolution, Data Alignment and number of conversion)
  */
  hadc3.Instance = ADC3;
  hadc3.Init.ClockPrescaler = ADC_CLOCK_SYNC_PCLK_DIV4;
  hadc3.Init.Resolution = ADC_RESOLUTION_12B;
  hadc3.Init.ScanConvMode = ADC_SCAN_DISABLE;
  hadc3.Init.ContinuousConvMode = DISABLE;
  hadc3.Init.DiscontinuousConvMode = DISABLE;
  hadc3.Init.ExternalTrigConvEdge = ADC_EXTERNALTRIGCONVEDGE_NONE;
  hadc3.Init.ExternalTrigConv = ADC_SOFTWARE_START;
  hadc3.Init.DataAlign = ADC_DATAALIGN_RIGHT;
  hadc3.Init.NbrOfConversion = 1;
  hadc3.Init.DMAContinuousRequests = DISABLE;
  hadc3.Init.EOCSelection = ADC_EOC_SINGLE_CONV;
  if (HAL_ADC_Init(&hadc3) != HAL_OK)
  {
    Error_Handler();
  }

  /** Configure for the selected ADC regular channel its corresponding rank in the sequencer and its sample time.
  */
  sConfig.Channel = ADC_CHANNEL_8;
  sConfig.Rank = ADC_REGULAR_RANK_1;
  sConfig.SamplingTime = ADC_SAMPLETIME_480CYCLES;
  if (HAL_ADC_ConfigChannel(&hadc3, &sConfig) != HAL_OK)
  {
    Error_Handler();
  }

}

static void MX_CRC_Init(void)
{

  hcrc.Instance = CRC;
  hcrc.Init.DefaultPolynomialUse = DEFAULT_POLYNOMIAL_ENABLE;
  hcrc.Init.DefaultInitValueUse = DEFAULT_INIT_VALUE_ENABLE;
  hcrc.Init.InputDataInversionMode = CRC_INPUTDATA_INVERSION_NONE;
  hcrc.Init.OutputDataInversionMode = CRC_OUTPUTDATA_INVERSION_DISABLE;
  hcrc.InputDataFormat = CRC_INPUTDATA_FORMAT_BYTES;
  if (HAL_CRC_Init(&hcrc) != HAL_OK)
  {
    Error_Handler();
  }

}

static void MX_DMA2D_Init(void)
{

  hdma2d.Instance = DMA2D;
  hdma2d.Init.Mode = DMA2D_M2M;
  hdma2d.Init.ColorMode = DMA2D_OUTPUT_ARGB8888;
  hdma2d.Init.OutputOffset = 0;
  hdma2d.LayerCfg[1].InputOffset = 0;
  hdma2d.LayerCfg[1].InputColorMode = DMA2D_INPUT_ARGB8888;
  hdma2d.LayerCfg[1].AlphaMode = DMA2D_NO_MODIF_ALPHA;
  hdma2d.LayerCfg[1].InputAlpha = 0;
  if (HAL_DMA2D_Init(&hdma2d) != HAL_OK)
  {
    Error_Handler();
  }
  if (HAL_DMA2D_ConfigLayer(&hdma2d, 1) != HAL_OK)
  {
    Error_Handler();
  }

}

static void MX_I2C1_Init(void)
{

  hi2c1.Instance = I2C1;
  hi2c1.Init.Timing = 0x00D0F4FF;
  hi2c1.Init.OwnAddress1 = 0;
  hi2c1.Init.AddressingMode = I2C_ADDRESSINGMODE_7BIT;
  hi2c1.Init.DualAddressMode = I2C_DUALADDRESS_DISABLE;
  hi2c1.Init.OwnAddress2 = 0;
  hi2c1.Init.OwnAddress2Masks = I2C_OA2_NOMASK;
  hi2c1.Init.GeneralCallMode = I2C_GENERALCALL_DISABLE;
  hi2c1.Init.NoStretchMode = I2C_NOSTRETCH_DISABLE;
  if (HAL_I2C_Init(&hi2c1) != HAL_OK)
  {
    Error_Handler();
  }

  /** Configure Analogue filter
  */
  if (HAL_I2CEx_ConfigAnalogFilter(&hi2c1, I2C_ANALOGFILTER_ENABLE) != HAL_OK)
  {
    Error_Handler();
  }

  /** Configure Digital filter
  */
  if (HAL_I2CEx_ConfigDigitalFilter(&hi2c1, 15) != HAL_OK)
  {
    Error_Handler();
  }

}

static void MX_I2C3_Init(void)
{

  /* USER CODE BEGIN I2C3_Init 0 */
  HAL_Delay(100); //Delay to fix initialization issue on some boards
  /* USER CODE END I2C3_Init 0 */

  hi2c3.Instance = I2C3;
  hi2c3.Init.Timing = 0x20404768;
  hi2c3.Init.OwnAddress1 = 0;
  hi2c3.Init.AddressingMode = I2C_ADDRESSINGMODE_7BIT;
  hi2c3.Init.DualAddressMode = I2C_DUALADDRESS_DISABLE;
  hi2c3.Init.OwnAddress2 = 0;
  hi2c3.Init.OwnAddress2Masks = I2C_OA2_NOMASK;
  hi2c3.Init.GeneralCallMode = I2C_GENERALCALL_DISABLE;
  hi2c3.Init.NoStretchMode = I2C_NOSTRETCH_DISABLE;
  if (HAL_I2C_Init(&hi2c3) != HAL_OK)
  {
    Error_Handler();
  }

  /** Configure Analogue filter
  */
  if (HAL_I2CEx_ConfigAnalogFilter(&hi2c3, I2C_ANALOGFILTER_ENABLE) != HAL_OK)
  {
    Error_Handler();
  }

  /** Configure Digital filter
  */
  if (HAL_I2CEx_ConfigDigitalFilter(&hi2c3, 0) != HAL_OK)
  {
    Error_Handler();
  }

}

static void MX_LTDC_Init(void)
{

  LTDC_LayerCfgTypeDef pLayerCfg = {0};

  hltdc.Instance = LTDC;
  hltdc.Init.HSPolarity = LTDC_HSPOLARITY_AL;
  hltdc.Init.VSPolarity = LTDC_VSPOLARITY_AL;
  hltdc.Init.DEPolarity = LTDC_DEPOLARITY_AL;
  hltdc.Init.PCPolarity = LTDC_PCPOLARITY_IPC;
  hltdc.Init.HorizontalSync = 40;
  hltdc.Init.VerticalSync = 9;
  hltdc.Init.AccumulatedHBP = 53;
  hltdc.Init.AccumulatedVBP = 11;
  hltdc.Init.AccumulatedActiveW = 533;
  hltdc.Init.AccumulatedActiveH = 283;
  hltdc.Init.TotalWidth = 565;
  hltdc.Init.TotalHeigh = 285;
  hltdc.Init.Backcolor.Blue = 0;
  hltdc.Init.Backcolor.Green = 0;
  hltdc.Init.Backcolor.Red = 0;
  if (HAL_LTDC_Init(&hltdc) != HAL_OK)
  {
    Error_Handler();
  }
  pLayerCfg.WindowX0 = 0;
  pLayerCfg.WindowX1 = 480;
  pLayerCfg.WindowY0 = 0;
  pLayerCfg.WindowY1 = 272;
  pLayerCfg.PixelFormat = LTDC_PIXEL_FORMAT_RGB565;
  pLayerCfg.Alpha = 255;
  pLayerCfg.Alpha0 = 0;
  pLayerCfg.BlendingFactor1 = LTDC_BLENDING_FACTOR1_CA;
  pLayerCfg.BlendingFactor2 = LTDC_BLENDING_FACTOR2_CA;
  pLayerCfg.FBStartAdress = 0xC0000000;
  pLayerCfg.ImageWidth = 480;
  pLayerCfg.ImageHeight = 272;
  pLayerCfg.Backcolor.Blue = 0;
  pLayerCfg.Backcolor.Green = 0;
  pLayerCfg.Backcolor.Red = 0;
  if (HAL_LTDC_ConfigLayer(&hltdc, &pLayerCfg, 0) != HAL_OK)
  {
    Error_Handler();
  }

}

static void MX_QUADSPI_Init(void)
{

  /* QUADSPI parameter configuration*/
  hqspi.Instance = QUADSPI;
  hqspi.Init.ClockPrescaler = 1;
  hqspi.Init.FifoThreshold = 4;
  hqspi.Init.SampleShifting = QSPI_SAMPLE_SHIFTING_HALFCYCLE;
  hqspi.Init.FlashSize = 24;
  hqspi.Init.ChipSelectHighTime = QSPI_CS_HIGH_TIME_6_CYCLE;
  hqspi.Init.ClockMode = QSPI_CLOCK_MODE_0;
  hqspi.Init.FlashID = QSPI_FLASH_ID_1;
  hqspi.Init.DualFlash = QSPI_DUALFLASH_DISABLE;
  if (HAL_QSPI_Init(&hqspi) != HAL_OK)
  {
    Error_Handler();
  }
  /* USER CODE BEGIN QUADSPI_Init 2 */
  uint8_t manufacturer_id;
  GetManufacturerId (&manufacturer_id);
  EnableMemoryMappedMode(manufacturer_id);
  HAL_NVIC_DisableIRQ(QUADSPI_IRQn);
  /* USER CODE END QUADSPI_Init 2 */

}

static void MX_TIM1_Init(void)
{

  TIM_ClockConfigTypeDef sClockSourceConfig = {0};
  TIM_MasterConfigTypeDef sMasterConfig = {0};
  TIM_OC_InitTypeDef sConfigOC = {0};
  TIM_BreakDeadTimeConfigTypeDef sBreakDeadTimeConfig = {0};

  htim1.Instance = TIM1;
  htim1.Init.Prescaler = 39;
  htim1.Init.CounterMode = TIM_COUNTERMODE_UP;
  htim1.Init.Period = 255;
  htim1.Init.ClockDivision = TIM_CLOCKDIVISION_DIV1;
  htim1.Init.RepetitionCounter = 0;
  htim1.Init.AutoReloadPreload = TIM_AUTORELOAD_PRELOAD_DISABLE;
  if (HAL_TIM_Base_Init(&htim1) != HAL_OK)
  {
    Error_Handler();
  }
  sClockSourceConfig.ClockSource = TIM_CLOCKSOURCE_INTERNAL;
  if (HAL_TIM_ConfigClockSource(&htim1, &sClockSourceConfig) != HAL_OK)
  {
    Error_Handler();
  }
  if (HAL_TIM_PWM_Init(&htim1) != HAL_OK)
  {
    Error_Handler();
  }
  sMasterConfig.MasterOutputTrigger = TIM_TRGO_RESET;
  sMasterConfig.MasterOutputTrigger2 = TIM_TRGO2_RESET;
  sMasterConfig.MasterSlaveMode = TIM_MASTERSLAVEMODE_DISABLE;
  if (HAL_TIMEx_MasterConfigSynchronization(&htim1, &sMasterConfig) != HAL_OK)
  {
    Error_Handler();
  }
  sConfigOC.OCMode = TIM_OCMODE_PWM1;
  sConfigOC.Pulse = 0;
  sConfigOC.OCPolarity = TIM_OCPOLARITY_HIGH;
  sConfigOC.OCNPolarity = TIM_OCNPOLARITY_HIGH;
  sConfigOC.OCFastMode = TIM_OCFAST_DISABLE;
  sConfigOC.OCIdleState = TIM_OCIDLESTATE_RESET;
  sConfigOC.OCNIdleState = TIM_OCNIDLESTATE_RESET;
  if (HAL_TIM_PWM_ConfigChannel(&htim1, &sConfigOC, TIM_CHANNEL_1) != HAL_OK)
  {
    Error_Handler();
  }
  sBreakDeadTimeConfig.OffStateRunMode = TIM_OSSR_DISABLE;
  sBreakDeadTimeConfig.OffStateIDLEMode = TIM_OSSI_DISABLE;
  sBreakDeadTimeConfig.LockLevel = TIM_LOCKLEVEL_OFF;
  sBreakDeadTimeConfig.DeadTime = 0;
  sBreakDeadTimeConfig.BreakState = TIM_BREAK_DISABLE;
  sBreakDeadTimeConfig.BreakPolarity = TIM_BREAKPOLARITY_HIGH;
  sBreakDeadTimeConfig.BreakFilter = 0;
  sBreakDeadTimeConfig.Break2State = TIM_BREAK2_DISABLE;
  sBreakDeadTimeConfig.Break2Polarity = TIM_BREAK2POLARITY_HIGH;
  sBreakDeadTimeConfig.Break2Filter = 0;
  sBreakDeadTimeConfig.AutomaticOutput = TIM_AUTOMATICOUTPUT_DISABLE;
  if (HAL_TIMEx_ConfigBreakDeadTime(&htim1, &sBreakDeadTimeConfig) != HAL_OK)
  {
    Error_Handler();
  }
  HAL_TIM_MspPostInit(&htim1);

}

static void MX_TIM2_Init(void)
{

  TIM_ClockConfigTypeDef sClockSourceConfig = {0};
  TIM_MasterConfigTypeDef sMasterConfig = {0};

  htim2.Instance = TIM2;
  htim2.Init.Prescaler = 107;
  htim2.Init.CounterMode = TIM_COUNTERMODE_UP;
  htim2.Init.Period = 4294967295;
  htim2.Init.ClockDivision = TIM_CLOCKDIVISION_DIV1;
  htim2.Init.AutoReloadPreload = TIM_AUTORELOAD_PRELOAD_DISABLE;
  if (HAL_TIM_Base_Init(&htim2) != HAL_OK)
  {
    Error_Handler();
  }
  sClockSourceConfig.ClockSource = TIM_CLOCKSOURCE_INTERNAL;
  if (HAL_TIM_ConfigClockSource(&htim2, &sClockSourceConfig) != HAL_OK)
  {
    Error_Handler();
  }
  sMasterConfig.MasterOutputTrigger = TIM_TRGO_RESET;
  sMasterConfig.MasterSlaveMode = TIM_MASTERSLAVEMODE_DISABLE;
  if (HAL_TIMEx_MasterConfigSynchronization(&htim2, &sMasterConfig) != HAL_OK)
  {
    Error_Handler();
  }

}

static void MX_TIM3_Init(void)
{

  TIM_ClockConfigTypeDef sClockSourceConfig = {0};
  TIM_MasterConfigTypeDef sMasterConfig = {0};
  TIM_OC_InitTypeDef sConfigOC = {0};

  htim3.Instance = TIM3;
  htim3.Init.Prescaler = 19;
  htim3.Init.CounterMode = TIM_COUNTERMODE_UP;
  htim3.Init.Period = 255;
  htim3.Init.ClockDivision = TIM_CLOCKDIVISION_DIV1;
  htim3.Init.AutoReloadPreload = TIM_AUTORELOAD_PRELOAD_DISABLE;
  if (HAL_TIM_Base_Init(&htim3) != HAL_OK)
  {
    Error_Handler();
  }
  sClockSourceConfig.ClockSource = TIM_CLOCKSOURCE_INTERNAL;
  if (HAL_TIM_ConfigClockSource(&htim3, &sClockSourceConfig) != HAL_OK)
  {
    Error_Handler();
  }
  if (HAL_TIM_PWM_Init(&htim3) != HAL_OK)
  {
    Error_Handler();
  }
  sMasterConfig.MasterOutputTrigger = TIM_TRGO_RESET;
  sMasterConfig.MasterSlaveMode = TIM_MASTERSLAVEMODE_DISABLE;
  if (HAL_TIMEx_MasterConfigSynchronization(&htim3, &sMasterConfig) != HAL_OK)
  {
    Error_Handler();
  }
  sConfigOC.OCMode = TIM_OCMODE_PWM1;
  sConfigOC.Pulse = 0;
  sConfigOC.OCPolarity = TIM_OCPOLARITY_HIGH;
  sConfigOC.OCFastMode = TIM_OCFAST_DISABLE;
  if (HAL_TIM_PWM_ConfigChannel(&htim3, &sConfigOC, TIM_CHANNEL_1) != HAL_OK)
  {
    Error_Handler();
  }
  HAL_TIM_MspPostInit(&htim3);

}

static void MX_TIM5_Init(void)
{

  TIM_ClockConfigTypeDef sClockSourceConfig = {0};
  TIM_MasterConfigTypeDef sMasterConfig = {0};
  TIM_OC_InitTypeDef sConfigOC = {0};

  htim5.Instance = TIM5;
  htim5.Init.Prescaler = 19;
  htim5.Init.CounterMode = TIM_COUNTERMODE_UP;
  htim5.Init.Period = 255;
  htim5.Init.ClockDivision = TIM_CLOCKDIVISION_DIV1;
  htim5.Init.AutoReloadPreload = TIM_AUTORELOAD_PRELOAD_DISABLE;
  if (HAL_TIM_Base_Init(&htim5) != HAL_OK)
  {
    Error_Handler();
  }
  sClockSourceConfig.ClockSource = TIM_CLOCKSOURCE_INTERNAL;
  if (HAL_TIM_ConfigClockSource(&htim5, &sClockSourceConfig) != HAL_OK)
  {
    Error_Handler();
  }
  if (HAL_TIM_PWM_Init(&htim5) != HAL_OK)
  {
    Error_Handler();
  }
  sMasterConfig.MasterOutputTrigger = TIM_TRGO_RESET;
  sMasterConfig.MasterSlaveMode = TIM_MASTERSLAVEMODE_DISABLE;
  if (HAL_TIMEx_MasterConfigSynchronization(&htim5, &sMasterConfig) != HAL_OK)
  {
    Error_Handler();
  }
  sConfigOC.OCMode = TIM_OCMODE_PWM1;
  sConfigOC.Pulse = 0;
  sConfigOC.OCPolarity = TIM_OCPOLARITY_HIGH;
  sConfigOC.OCFastMode = TIM_OCFAST_DISABLE;
  if (HAL_TIM_PWM_ConfigChannel(&htim5, &sConfigOC, TIM_CHANNEL_4) != HAL_OK)
  {
    Error_Handler();
  }
  HAL_TIM_MspPostInit(&htim5);

}

static void MX_TIM8_Init(void)
{

  TIM_ClockConfigTypeDef sClockSourceConfig = {0};
  TIM_MasterConfigTypeDef sMasterConfig = {0};

  htim8.Instance = TIM8;
  htim8.Init.Prescaler = 0;
  htim8.Init.CounterMode = TIM_COUNTERMODE_UP;
  htim8.Init.Period = 65535;
  htim8.Init.ClockDivision = TIM_CLOCKDIVISION_DIV1;
  htim8.Init.RepetitionCounter = 0;
  htim8.Init.AutoReloadPreload = TIM_AUTORELOAD_PRELOAD_DISABLE;
  if (HAL_TIM_Base_Init(&htim8) != HAL_OK)
  {
    Error_Handler();
  }
  sClockSourceConfig.ClockSource = TIM_CLOCKSOURCE_INTERNAL;
  if (HAL_TIM_ConfigClockSource(&htim8, &sClockSourceConfig) != HAL_OK)
  {
    Error_Handler();
  }
  sMasterConfig.MasterOutputTrigger = TIM_TRGO_RESET;
  sMasterConfig.MasterOutputTrigger2 = TIM_TRGO2_RESET;
  sMasterConfig.MasterSlaveMode = TIM_MASTERSLAVEMODE_DISABLE;
  if (HAL_TIMEx_MasterConfigSynchronization(&htim8, &sMasterConfig) != HAL_OK)
  {
    Error_Handler();
  }

}

static void MX_TIM12_Init(void)
{

  TIM_ClockConfigTypeDef sClockSourceConfig = {0};
  TIM_OC_InitTypeDef sConfigOC = {0};

  htim12.Instance = TIM12;
  htim12.Init.Prescaler = 19;
  htim12.Init.CounterMode = TIM_COUNTERMODE_UP;
  htim12.Init.Period = 255;
  htim12.Init.ClockDivision = TIM_CLOCKDIVISION_DIV1;
  htim12.Init.AutoReloadPreload = TIM_AUTORELOAD_PRELOAD_DISABLE;
  if (HAL_TIM_Base_Init(&htim12) != HAL_OK)
  {
    Error_Handler();
  }
  sClockSourceConfig.ClockSource = TIM_CLOCKSOURCE_INTERNAL;
  if (HAL_TIM_ConfigClockSource(&htim12, &sClockSourceConfig) != HAL_OK)
  {
    Error_Handler();
  }
  if (HAL_TIM_PWM_Init(&htim12) != HAL_OK)
  {
    Error_Handler();
  }
  sConfigOC.OCMode = TIM_OCMODE_PWM1;
  sConfigOC.Pulse = 0;
  sConfigOC.OCPolarity = TIM_OCPOLARITY_HIGH;
  sConfigOC.OCFastMode = TIM_OCFAST_DISABLE;
  if (HAL_TIM_PWM_ConfigChannel(&htim12, &sConfigOC, TIM_CHANNEL_2) != HAL_OK)
  {
    Error_Handler();
  }
  HAL_TIM_MspPostInit(&htim12);

}

static void MX_TIM13_Init(void)
{

  htim13.Instance = TIM13;
  htim13.Init.Prescaler = 0;
  htim13.Init.CounterMode = TIM_COUNTERMODE_UP;
  htim13.Init.Period = 65535;
  htim13.Init.ClockDivision = TIM_CLOCKDIVISION_DIV1;
  htim13.Init.AutoReloadPreload = TIM_AUTORELOAD_PRELOAD_DISABLE;
  if (HAL_TIM_Base_Init(&htim13) != HAL_OK)
  {
    Error_Handler();
  }

}

static void MX_USART1_UART_Init(void)
{

  huart1.Instance = USART1;
  huart1.Init.BaudRate = 115200;
  huart1.Init.WordLength = UART_WORDLENGTH_8B;
  huart1.Init.StopBits = UART_STOPBITS_1;
  huart1.Init.Parity = UART_PARITY_NONE;
  huart1.Init.Mode = UART_MODE_TX_RX;
  huart1.Init.HwFlowCtl = UART_HWCONTROL_NONE;
  huart1.Init.OverSampling = UART_OVERSAMPLING_16;
  huart1.Init.OneBitSampling = UART_ONE_BIT_SAMPLE_DISABLE;
  huart1.AdvancedInit.AdvFeatureInit = UART_ADVFEATURE_NO_INIT;
  if (HAL_UART_Init(&huart1) != HAL_OK)
  {
    Error_Handler();
  }
  /* USER CODE BEGIN USART1_Init 2 */
  // HAL_UART_Receive_IT (Protocol_UartRxHandler) icin USART1 kesmesini etkinlestir
  HAL_NVIC_SetPriority(USART1_IRQn, 5, 0);
  HAL_NVIC_EnableIRQ(USART1_IRQn);
  /* USER CODE END USART1_Init 2 */

}

static void MX_USART6_UART_Init(void)
{

  huart6.Instance = USART6;
  huart6.Init.BaudRate = 9600;
  huart6.Init.WordLength = UART_WORDLENGTH_8B;
  huart6.Init.StopBits = UART_STOPBITS_1;
  huart6.Init.Parity = UART_PARITY_NONE;
  huart6.Init.Mode = UART_MODE_TX_RX;
  huart6.Init.HwFlowCtl = UART_HWCONTROL_NONE;
  huart6.Init.OverSampling = UART_OVERSAMPLING_16;
  huart6.Init.OneBitSampling = UART_ONE_BIT_SAMPLE_DISABLE;
  huart6.AdvancedInit.AdvFeatureInit = UART_ADVFEATURE_NO_INIT;
  if (HAL_UART_Init(&huart6) != HAL_OK)
  {
    Error_Handler();
  }

}

/* FMC initialization function */
static void MX_FMC_Init(void)
{

  FMC_SDRAM_TimingTypeDef SdramTiming = {0};

  /** Perform the SDRAM1 memory initialization sequence
  */
  hsdram1.Instance = FMC_SDRAM_DEVICE;
  /* hsdram1.Init */
  hsdram1.Init.SDBank = FMC_SDRAM_BANK1;
  hsdram1.Init.ColumnBitsNumber = FMC_SDRAM_COLUMN_BITS_NUM_8;
  hsdram1.Init.RowBitsNumber = FMC_SDRAM_ROW_BITS_NUM_12;
  hsdram1.Init.MemoryDataWidth = FMC_SDRAM_MEM_BUS_WIDTH_16;
  hsdram1.Init.InternalBankNumber = FMC_SDRAM_INTERN_BANKS_NUM_4;
  hsdram1.Init.CASLatency = FMC_SDRAM_CAS_LATENCY_3;
  hsdram1.Init.WriteProtection = FMC_SDRAM_WRITE_PROTECTION_DISABLE;
  hsdram1.Init.SDClockPeriod = FMC_SDRAM_CLOCK_PERIOD_2;
  hsdram1.Init.ReadBurst = FMC_SDRAM_RBURST_ENABLE;
  hsdram1.Init.ReadPipeDelay = FMC_SDRAM_RPIPE_DELAY_0;
  /* SdramTiming */
  SdramTiming.LoadToActiveDelay = 2;
  SdramTiming.ExitSelfRefreshDelay = 7;
  SdramTiming.SelfRefreshTime = 4;
  SdramTiming.RowCycleDelay = 7;
  SdramTiming.WriteRecoveryTime = 3;
  SdramTiming.RPDelay = 2;
  SdramTiming.RCDDelay = 2;

  if (HAL_SDRAM_Init(&hsdram1, &SdramTiming) != HAL_OK)
  {
    Error_Handler( );
  }

  /* USER CODE BEGIN FMC_Init 2 */
  __IO uint32_t tmpmrd = 0;

    /* Step 1: Configure a clock configuration enable command */
    Command.CommandMode            = FMC_SDRAM_CMD_CLK_ENABLE;
    Command.CommandTarget          =  FMC_SDRAM_CMD_TARGET_BANK1;
    Command.AutoRefreshNumber      = 1;
    Command.ModeRegisterDefinition = 0;

    /* Send the command */
    HAL_SDRAM_SendCommand(&hsdram1, &Command, SDRAM_TIMEOUT);

    /* Step 2: Insert 100 us minimum delay */
    /* Inserted delay is equal to 1 ms due to systick time base unit (ms) */
    HAL_Delay(1);

    /* Step 3: Configure a PALL (precharge all) command */
    Command.CommandMode            = FMC_SDRAM_CMD_PALL;
    Command.CommandTarget          = FMC_SDRAM_CMD_TARGET_BANK1;
    Command.AutoRefreshNumber      = 1;
    Command.ModeRegisterDefinition = 0;

    /* Send the command */
    HAL_SDRAM_SendCommand(&hsdram1, &Command, SDRAM_TIMEOUT);

    /* Step 4: Configure an Auto Refresh command */
    Command.CommandMode            = FMC_SDRAM_CMD_AUTOREFRESH_MODE;
    Command.CommandTarget          = FMC_SDRAM_CMD_TARGET_BANK1;
    Command.AutoRefreshNumber      = 8;
    Command.ModeRegisterDefinition = 0;

    /* Send the command */
    HAL_SDRAM_SendCommand(&hsdram1, &Command, SDRAM_TIMEOUT);

    /* Step 5: Program the external memory mode register */
    tmpmrd = (uint32_t)SDRAM_MODEREG_BURST_LENGTH_1 | \
             SDRAM_MODEREG_BURST_TYPE_SEQUENTIAL    | \
             SDRAM_MODEREG_CAS_LATENCY_3            | \
             SDRAM_MODEREG_OPERATING_MODE_STANDARD  | \
             SDRAM_MODEREG_WRITEBURST_MODE_SINGLE;

    Command.CommandMode            = FMC_SDRAM_CMD_LOAD_MODE;
    Command.CommandTarget          = FMC_SDRAM_CMD_TARGET_BANK1;
    Command.AutoRefreshNumber      = 1;
    Command.ModeRegisterDefinition = tmpmrd;

    /* Send the command */
    HAL_SDRAM_SendCommand(&hsdram1, &Command, SDRAM_TIMEOUT);

    /* Step 6: Set the refresh rate counter */
    /* Set the device refresh rate */
    HAL_SDRAM_ProgramRefreshRate(&hsdram1, REFRESH_COUNT);

    //Deactivate speculative/cache access to first FMC Bank to save FMC bandwidth
    FMC_Bank1->BTCR[0] = 0x000030D2;
  /* USER CODE END FMC_Init 2 */
}

static void MX_GPIO_Init(void)
{
  GPIO_InitTypeDef GPIO_InitStruct = {0};

  /* GPIO Ports Clock Enable */
  __HAL_RCC_GPIOE_CLK_ENABLE();
  __HAL_RCC_GPIOB_CLK_ENABLE();
  __HAL_RCC_GPIOA_CLK_ENABLE();
  __HAL_RCC_GPIOG_CLK_ENABLE();
  __HAL_RCC_GPIOJ_CLK_ENABLE();
  __HAL_RCC_GPIOD_CLK_ENABLE();
  __HAL_RCC_GPIOK_CLK_ENABLE();
  __HAL_RCC_GPIOI_CLK_ENABLE();
  __HAL_RCC_GPIOF_CLK_ENABLE();
  __HAL_RCC_GPIOH_CLK_ENABLE();
  __HAL_RCC_GPIOC_CLK_ENABLE();

  /*Configure GPIO pin Output Level */
  HAL_GPIO_WritePin(GPIOA, GPIO_PIN_15, GPIO_PIN_RESET);

  /*Configure GPIO pin Output Level */
  HAL_GPIO_WritePin(LCD_BL_CTRL_GPIO_Port, LCD_BL_CTRL_Pin, GPIO_PIN_SET);

  /*Configure GPIO pin Output Level */
  HAL_GPIO_WritePin(GPIOI, GPIO_PIN_1, GPIO_PIN_RESET);

  /*Configure GPIO pin Output Level */
  HAL_GPIO_WritePin(LCD_DISP_GPIO_Port, LCD_DISP_Pin, GPIO_PIN_SET);

  /*Configure GPIO pin Output Level */
  HAL_GPIO_WritePin(GPIOG, GPIO_PIN_7, GPIO_PIN_RESET);

  /*Configure GPIO pin Output Level */
  HAL_GPIO_WritePin(GPIOF, GPIO_PIN_7|GPIO_PIN_6|GPIO_PIN_8, GPIO_PIN_RESET);

  /*Configure GPIO pin Output Level */
  HAL_GPIO_WritePin(GPIOH, GPIO_PIN_6, GPIO_PIN_RESET);

  /*Configure GPIO pin Output Level */
  HAL_GPIO_WritePin(GPIOB, GPIO_PIN_14, GPIO_PIN_RESET);

  /*Configure GPIO pin : PA15 */
  GPIO_InitStruct.Pin = GPIO_PIN_15;
  GPIO_InitStruct.Mode = GPIO_MODE_OUTPUT_PP;
  GPIO_InitStruct.Pull = GPIO_NOPULL;
  GPIO_InitStruct.Speed = GPIO_SPEED_FREQ_LOW;
  HAL_GPIO_Init(GPIOA, &GPIO_InitStruct);

  /*Configure GPIO pins : PI3 PI2 */
  GPIO_InitStruct.Pin = GPIO_PIN_3|GPIO_PIN_2;
  GPIO_InitStruct.Mode = GPIO_MODE_IT_RISING;
  GPIO_InitStruct.Pull = GPIO_PULLUP;
  HAL_GPIO_Init(GPIOI, &GPIO_InitStruct);

  /*Configure GPIO pin : LCD_BL_CTRL_Pin */
  GPIO_InitStruct.Pin = LCD_BL_CTRL_Pin;
  GPIO_InitStruct.Mode = GPIO_MODE_OUTPUT_PP;
  GPIO_InitStruct.Pull = GPIO_NOPULL;
  GPIO_InitStruct.Speed = GPIO_SPEED_FREQ_LOW;
  HAL_GPIO_Init(LCD_BL_CTRL_GPIO_Port, &GPIO_InitStruct);

  /*Configure GPIO pins : PI1 LCD_DISP_Pin */
  GPIO_InitStruct.Pin = GPIO_PIN_1|LCD_DISP_Pin;
  GPIO_InitStruct.Mode = GPIO_MODE_OUTPUT_PP;
  GPIO_InitStruct.Pull = GPIO_NOPULL;
  GPIO_InitStruct.Speed = GPIO_SPEED_FREQ_LOW;
  HAL_GPIO_Init(GPIOI, &GPIO_InitStruct);

  /*Configure GPIO pin : PG7 */
  GPIO_InitStruct.Pin = GPIO_PIN_7;
  GPIO_InitStruct.Mode = GPIO_MODE_OUTPUT_PP;
  GPIO_InitStruct.Pull = GPIO_NOPULL;
  GPIO_InitStruct.Speed = GPIO_SPEED_FREQ_LOW;
  HAL_GPIO_Init(GPIOG, &GPIO_InitStruct);

  /*Configure GPIO pin : LOAD_DETECTED_Pin */
  GPIO_InitStruct.Pin = LOAD_DETECTED_Pin;
  GPIO_InitStruct.Mode = GPIO_MODE_INPUT;
  GPIO_InitStruct.Pull = GPIO_PULLUP;
  HAL_GPIO_Init(LOAD_DETECTED_GPIO_Port, &GPIO_InitStruct);

  /*Configure GPIO pins : PF7 PF6 PF8 */
  GPIO_InitStruct.Pin = GPIO_PIN_7|GPIO_PIN_6|GPIO_PIN_8;
  GPIO_InitStruct.Mode = GPIO_MODE_OUTPUT_PP;
  GPIO_InitStruct.Pull = GPIO_NOPULL;
  GPIO_InitStruct.Speed = GPIO_SPEED_FREQ_LOW;
  HAL_GPIO_Init(GPIOF, &GPIO_InitStruct);

  /*Configure GPIO pin : PH6 */
  GPIO_InitStruct.Pin = GPIO_PIN_6;
  GPIO_InitStruct.Mode = GPIO_MODE_OUTPUT_PP;
  GPIO_InitStruct.Pull = GPIO_NOPULL;
  GPIO_InitStruct.Speed = GPIO_SPEED_FREQ_LOW;
  HAL_GPIO_Init(GPIOH, &GPIO_InitStruct);

  /*Configure GPIO pin : PB14 */
  GPIO_InitStruct.Pin = GPIO_PIN_14;
  GPIO_InitStruct.Mode = GPIO_MODE_OUTPUT_PP;
  GPIO_InitStruct.Pull = GPIO_NOPULL;
  GPIO_InitStruct.Speed = GPIO_SPEED_FREQ_LOW;
  HAL_GPIO_Init(GPIOB, &GPIO_InitStruct);

  /* EXTI interrupt init*/
  HAL_NVIC_SetPriority(EXTI2_IRQn, 5, 0);
  HAL_NVIC_EnableIRQ(EXTI2_IRQn);

  HAL_NVIC_SetPriority(EXTI3_IRQn, 5, 0);
  HAL_NVIC_EnableIRQ(EXTI3_IRQn);

}

/* USER CODE BEGIN 4 */

// Read manufacturer ID of external QSPI flash
void GetManufacturerId (uint8_t *manufacturer_id)
{
  QSPI_CommandTypeDef s_command_id;

  /* Initialize the read flag status register command */
  s_command_id.InstructionMode   = QSPI_INSTRUCTION_1_LINE;
  s_command_id.Instruction       = FLASH_READ_JEDEC_ID;
  s_command_id.AddressMode       = QSPI_ADDRESS_NONE;
  s_command_id.AlternateByteMode = QSPI_ALTERNATE_BYTES_NONE;
  s_command_id.DataMode          = QSPI_DATA_1_LINE;
  s_command_id.DummyCycles       = 0;
  s_command_id.NbData            = 1;
  s_command_id.DdrMode           = QSPI_DDR_MODE_DISABLE;
  s_command_id.DdrHoldHalfCycle  = QSPI_DDR_HHC_ANALOG_DELAY;
  s_command_id.SIOOMode          = QSPI_SIOO_INST_EVERY_CMD;

  /* Configure the command */
  if (HAL_QSPI_Command(&hqspi, &s_command_id, HAL_QPSI_TIMEOUT_DEFAULT_VALUE) != HAL_OK)
  {
	  Error_Handler();
  }

  /* Reception of the data */
  if (HAL_QSPI_Receive(&hqspi, manufacturer_id, HAL_QPSI_TIMEOUT_DEFAULT_VALUE) != HAL_OK)
  {
	  Error_Handler();
  }
}

// Enable memory mapped mode for external QSPI flash
void EnableMemoryMappedMode(uint8_t manufacturer_id)
{
  QSPI_CommandTypeDef      s_command;
  QSPI_MemoryMappedTypeDef s_mem_mapped_cfg;

  /* Configure the command for the read instruction */
  s_command.InstructionMode   = QSPI_INSTRUCTION_1_LINE;
  s_command.Instruction       = FLASH_FAST_READ_QUAD_IO;
  s_command.AddressMode       = QSPI_ADDRESS_4_LINES;
  s_command.AddressSize       = QSPI_ADDRESS_24_BITS;
  s_command.AlternateByteMode = QSPI_ALTERNATE_BYTES_NONE;
  s_command.DataMode          = QSPI_DATA_4_LINES;

  // Set dummy cycles according to manufacturer ID
  s_command.DummyCycles       = manufacturer_id == FLASH_REVC03_MANUFACTURER_ID ? FLASH_W25Q128J_DUMMY_CYCLES : FLASH_N25Q128A_DUMMY_CYCLES;

  s_command.DdrMode           = QSPI_DDR_MODE_DISABLE;
  s_command.DdrHoldHalfCycle  = QSPI_DDR_HHC_ANALOG_DELAY;
  s_command.SIOOMode          = QSPI_SIOO_INST_EVERY_CMD;

  /* Configure the memory mapped mode */
  s_mem_mapped_cfg.TimeOutActivation = QSPI_TIMEOUT_COUNTER_DISABLE;
  s_mem_mapped_cfg.TimeOutPeriod     = 0;

  if (HAL_QSPI_MemoryMapped(&hqspi, &s_command, &s_mem_mapped_cfg) != HAL_OK)
  {
    Error_Handler();
  }
}

/* Encoder Okuma Callback */
void HAL_GPIO_EXTI_Callback(uint16_t GPIO_Pin) {
    MotorControl_EncoderExtiCallback(GPIO_Pin);
}

/* USART1 (Orange Pi binary protokol) + USART6 (Bluetooth) Veri Alma Callback */
void HAL_UART_RxCpltCallback(UART_HandleTypeDef *huart)
{
    MotorTargetCommand_t command;

    if (huart->Instance == USART1)
    {
        // USART1 sadece Orange Pi binary protokoluene ait
        Protocol_UartRxHandler(&g_protocol, rx_byte_dma);
        HAL_UART_Receive_IT(&huart1, &rx_byte_dma, 1);
        return;
    }

    // USART6 (Bluetooth / HC-06) - manuel kontrol
    if (huart->Instance == USART6)
    {
        bool drive_packet_received = false;
        UartCom_BluetoothRxCallback(huart, &command, &drive_packet_received);

        if (drive_packet_received)
        {
            manual_last_command_tick = HAL_GetTick();
            left_target = command.left_pwm;
            right_target = command.right_pwm;
        }
    }
}

void HAL_UART_ErrorCallback(UART_HandleTypeDef *huart)
{
  if (huart->Instance == USART1)
  {
    volatile uint32_t dummy = huart->Instance->RDR;
    (void)dummy;
    HAL_UART_Receive_IT(&huart1, &rx_byte_dma, 1);
  }
}

/* USER CODE BEGIN Header_StartProtocolTask */
/**
  * @brief  UART protokol gorevi (Orange Pi <-> STM32 binary protokolu).
  *         Odometry/status periyodik gonderimi, hiz/fork/safety komutlarinin
  *         islenmesi ve watchdog kontrolu bu thread icinde yapilir.
  * @param  argument: Not used
  * @retval None
  */
/* USER CODE END Header_StartProtocolTask */

void StartImuTask(void *argument)
{
  TickType_t xLastWakeTime;
  const TickType_t xFrequency = pdMS_TO_TICKS(20); // 50 Hz

  uint8_t error_count = 0;
  uint32_t last_cycle_count = DWT->CYCCNT;
  uint32_t imu_time_us = 0U;
  xLastWakeTime = xTaskGetTickCount();

  for (;;)
  {
    if (imu_is_ready)
    {
        uint32_t current_cycle_count = DWT->CYCCNT;
        uint32_t elapsed_cycles = current_cycle_count - last_cycle_count;
        last_cycle_count = current_cycle_count;
        imu_time_us += elapsed_cycles / (SystemCoreClock / 1000000U);

        if (Fusion_Update(&imu_fusion, &hmpu1, imu_time_us) == HAL_OK)
        {
            error_count = 0;
            g_shared_imu_yaw = imu_fusion.yaw;
        }
        else
        {
            // Okuma başarısız, NAN ataması kaldırıldı. Eski g_shared_imu_yaw değeri korunur.
            error_count++;
        }
    }
    else
    {
        // Bağlantı yok, NAN ataması kaldırıldı. Eski değer korunur.
        error_count++;
    }

    // Ardışık hatalar eşiğe ulaştığında hattı anında resetle
    if (error_count >= 2)
    {
        error_count = 0;

        MPU9250_I2C_Hard_Reset(&hi2c1);

        hi2c1.ErrorCode = HAL_I2C_ERROR_NONE;
        hi2c1.State = HAL_I2C_STATE_READY;
        hi2c1.PreviousState = HAL_I2C_MODE_NONE;
        hi2c1.Mode = HAL_I2C_MODE_NONE;

        imu_is_ready = (MPU9250_Init(&hmpu1, &hi2c1, ACCEL_FS_4G,
                                     GYRO_FS_500DPS) == HAL_OK);

        // if (!imu_is_ready) içerisindeki NAN ataması kaldırıldı.

        imu_fusion.first_update = 1U;
        //last_cycle_count = DWT->CYCCNT;
    }

    vTaskDelayUntil(&xLastWakeTime, xFrequency);
  }
}

void StartBatteryTask(void *argument)
{
  for (;;)
  {
      // ADC1 üzerinden okuma yapıldığı varsayılmıştır.
      // Fonksiyon kendi içerisinde güvenli ortalama ve filtreleme yapıyor.
      aku_voltaji = Battery_GetVoltage(&hadc1);

      // Status gönderiminde kullanılmak üzere değeri milivolt (int) cinsine çevirip saklıyoruz
      battery_mv = (int)(aku_voltaji * 1000.0f) + 840;

      // Batarya ölçümünü saniyede 1 kez (1000 ms) yapmak yeterlidir
      osDelay(1000);
  }
}

void StartProtocolTask(void *argument)
{
  uint32_t last_odom_tick = HAL_GetTick();
  uint32_t last_status_tick = HAL_GetTick();

  const uint32_t odom_interval_ms = 10;    /* 100 Hz */
  const uint32_t status_interval_ms = 100; /* 10 Hz */

  for (;;)
  {
    uint32_t current_tick = HAL_GetTick();

    /* 1. Watchdog ve hiz komutu ayni kritik bolgede ele alinir; UART ISR'i
     * bes baytlik komut okunurken yapinin yarisini degistiremez. */
    CmdVelocity_t velocity_command = {0};
    bool has_velocity_command = false;
    __disable_irq();
    Protocol_UpdateWatchdog(&g_protocol, current_tick);
    if (g_protocol.new_cmd_velocity_flag)
    {
      g_protocol.new_cmd_velocity_flag = false;
      velocity_command = g_protocol.cmd_velocity;
      has_velocity_command = true;
    }
    __enable_irq();

    /* 2. Gelen Komutların İşlenmesi */
    if (has_velocity_command)
    {
      if (((velocity_command.flags & FLAG_MOTORS_ENABLED) != 0U) &&
          !soft_estop_latched)
      {
        opi_left_target = velocity_command.left_target;
        /* Sag motor fiziksel yerlesimde ters monte. */
        opi_right_target = -velocity_command.right_target;
      }
      else
      {
        opi_left_target = 0.0f;
        opi_right_target = 0.0f;
      }
    }

    CmdFork_t fork_command = {0};
    bool has_fork_command = false;
    __disable_irq();
    if (g_protocol.new_cmd_fork_flag)
    {
      g_protocol.new_cmd_fork_flag = false;
      fork_command = g_protocol.cmd_fork;
      has_fork_command = true;
    }
    __enable_irq();

    if (has_fork_command)
    {
      uint8_t  action     = fork_command.action;
      uint16_t timeout_ms = fork_command.timeout_ms;

      switch (action)
      {
        case FORK_ACTION_STOP:
          LiftLineer_Stop();
          EgimLineer_Stop();
          fork_timeout_active = false;
          BuzzerControl_SetMode(BUZZER_MODE_SILENT);
          break;
        case FORK_ACTION_UP:
          EgimLineer_Stop();
          LiftLineer_Up(LIFT_DEFAULT_SPEED);
          fork_action_start_tick = current_tick;
          fork_active_timeout_ms = timeout_ms;
          fork_timeout_active    = (timeout_ms > 0U);
          BuzzerControl_SetMode(BUZZER_MODE_LOAD_PICKUP);
          break;
        case FORK_ACTION_DOWN:
          EgimLineer_Stop();
          LiftLineer_Down(LIFT_DEFAULT_SPEED);
          fork_action_start_tick = current_tick;
          fork_active_timeout_ms = timeout_ms;
          fork_timeout_active    = (timeout_ms > 0U);
          BuzzerControl_SetMode(BUZZER_MODE_LOAD_DROP);
          break;
        case FORK_ACTION_TILT_UP:
          LiftLineer_Stop();
          EgimLineer_Up(EGIM_DEFAULT_SPEED);
          fork_action_start_tick = current_tick;
          fork_active_timeout_ms = timeout_ms;
          fork_timeout_active    = (timeout_ms > 0U);
          BuzzerControl_SetMode(BUZZER_MODE_SILENT);
          break;
        case FORK_ACTION_TILT_DOWN:
          LiftLineer_Stop();
          EgimLineer_Down(EGIM_DEFAULT_SPEED);
          fork_action_start_tick = current_tick;
          fork_active_timeout_ms = timeout_ms;
          fork_timeout_active    = (timeout_ms > 0U);
          BuzzerControl_SetMode(BUZZER_MODE_LOAD_DROP);
          break;
        default:
          LiftLineer_Stop();
          EgimLineer_Stop();
          fork_timeout_active = false;
          BuzzerControl_SetMode(BUZZER_MODE_SILENT);
          break;
      }
    }

    if (fork_timeout_active && ((current_tick - fork_action_start_tick) >= fork_active_timeout_ms))
    {
      LiftLineer_Stop();
      EgimLineer_Stop();
      fork_timeout_active = false;
    }

    CmdSafety_t safety_command = {0};
    bool has_safety_command = false;
    __disable_irq();
    if (g_protocol.new_cmd_safety_flag)
    {
      g_protocol.new_cmd_safety_flag = false;
      safety_command = g_protocol.cmd_safety;
      has_safety_command = true;
    }
    __enable_irq();

    if (has_safety_command)
    {
      if (safety_command.command == 1U) /* SOFT_ESTOP */
      {
          soft_estop_latched = true;
          opi_left_target = 0.0f;
          opi_right_target = 0.0f;
          LiftLineer_Stop();
          EgimLineer_Stop();
          fork_timeout_active = false;
      }
      else if (safety_command.command == 2U) /* CLEAR_FAULT */
      {
          soft_estop_latched = false;
      }
    }

    if (g_protocol.heartbeat_received_flag)
    {
      g_protocol.heartbeat_received_flag = false;
    }

    /* 3. ODOMETRY GÖNDERİMİ (100 Hz) - Süreyi uzatan IMU update buradan taşındı */
    if ((current_tick - last_odom_tick) >= odom_interval_ms)
    {
      last_odom_tick = current_tick;

      // NOT: Fusion_Update burada her 10ms'de bir bloğa sebep oluyorsa,
      // IMU'yu ayrı bir taskte veya DMA/Interrupt ile güncelleyip buraya sadece
      // anlık 'imu_fusion.yaw' değerini okutmalısın.

      int32_t left_ticks_snapshot;
      int32_t right_ticks_snapshot;
      uint32_t primask = __get_PRIMASK();
      __disable_irq();
      left_ticks_snapshot = MotorControl_GetLeftOdoTicks();
      right_ticks_snapshot = MotorControl_GetRightOdoTicks();
      if (primask == 0U) __enable_irq();

      StateOdometry_t reply_odo = {
          .timestamp_us = (uint64_t)current_tick * 1000,
          .left_ticks   = left_ticks_snapshot,
          .right_ticks  = -1 * right_ticks_snapshot,
          .left_speed   = MotorControl_GetLeftMeasuredMmPs(),
          .right_speed  = -MotorControl_GetRightMeasuredMmPs(),
          .imu_yaw      = g_shared_imu_yaw
      };
      Protocol_DirectSend_Odometry(&g_protocol, &reply_odo);
    }

    /* 4. STATUS GÖNDERİMİ (10 Hz) */
    if ((current_tick - last_status_tick) >= status_interval_ms)
        {
          last_status_tick = current_tick;

          // === ACS712 AKIM OKUMASI BURAYA EKLENİYOR ===
          // Sensörünüz ADC3'e bağlı ise &hadc3, başka ADC ise ona göre değiştirin
          g_forklift_akim = ACS712_ReadCurrent(&hadc3);

          uint16_t status_flags = 0U;

          bool manual_active=!g_is_autonomous_mode;

          if (soft_estop_latched) status_flags |= STATUS_FLAG_ESTOP_ACTIVE;
          if (manual_active) status_flags |= STATUS_FLAG_MODE_MANUAL;
          if (MotorControl_IsEnabled()) status_flags |= STATUS_FLAG_MOTORS_ENABLED;
          if (g_protocol.watchdog_triggered) status_flags |= STATUS_FLAG_WATCHDOG_TRIGGERED;
          if (MotorControl_WasCommandClamped()) status_flags |= STATUS_FLAG_CMD_CLAMPED;
          if (MotorControl_HasEncoderFault()) status_flags |= STATUS_FLAG_ENCODER_FAULT;
          if (HAL_GPIO_ReadPin(LOAD_DETECTED_GPIO_Port, LOAD_DETECTED_Pin) == GPIO_PIN_RESET)
          {
              status_flags |= STATUS_FLAG_LOAD_DETECTED;
          }

          // Akım değerini (amper) miliampere çevirerek protokole yüklüyoruz
          int16_t akim_ma = (int16_t)(g_forklift_akim * 1000.0f);

          StateStatus_t reply_status = {
              .timestamp_us     = current_tick * 1000U,
              .flags            = status_flags,
              .battery_mv       = battery_mv,
              .current_ma_left  = akim_ma,  // Orange Pi artık akımı buradan görecek
              .current_ma_right = 0,        // Eğer ikinci bir sensör takarsanız buraya eklersiniz
              .temperature_c    = 0,
              .fork_state       = g_protocol.cmd_fork.action
          };

          Protocol_DirectSend_Status(&g_protocol, &reply_status);
        }
    /*
     * KRİTİK DÜZELTME:
     * İşlem uzun sürüyorsa osDelay(1) yerine kalan süreyi esnetmek veya
     * işlem maliyetini düşürmek gerekir. Eğer odom_interval_ms (10ms) süresini
     * milisaniye hassasiyetinde tutmak istiyorsan task'i boşa yormamak adına
     * buradaki gecikmeyi optimize etmelisin.
     */
    osDelay(1);
  }
}

/*void StartAht10Task(void *argument)
{
  TickType_t xLastWakeTime;
  const TickType_t xFrequency = pdMS_TO_TICKS(2000); // 2 saniyede bir okuma

  xLastWakeTime = xTaskGetTickCount();

  for (;;)
  {
    if (g_aht10_is_ready)
    {
        float temp = 0.0f;
        float hum = 0.0f;

        // AHT10_Read void döndüğü için doğrudan çağırıyoruz
        AHT10_Read(&aht10_sensor, &temp, &hum);

        // Değerleri global değişkenlere aktarıyoruz
        g_aht10_temperature = temp;
        g_aht10_humidity = hum;
    }

    // Belirlenen periyot boyunca task'ı uykuya al
    vTaskDelayUntil(&xLastWakeTime, xFrequency);
  }
}*/
/* USER CODE END 4 */

void StartDefaultTask(void *argument)
{
  /* USER CODE BEGIN 5 */
	float prev_final_left = 0.0f;
	float prev_final_right = 0.0f;

  /* Infinite loop */
  for(;;)
  {
	  float final_left = 0.0f;
	  float final_right = 0.0f;
      uint32_t now_tick = HAL_GetTick();

      if (((left_target != 0) || (right_target != 0)) &&
          ((now_tick - manual_last_command_tick) >= MANUAL_COMMAND_TIMEOUT_MS))
      {
          left_target = 0;
          right_target = 0;
      }

      /* ---- KONTROL YONETICISI (MUX) ---- */
      // Oncelik 1: Yazilimsal acil durus butun kaynaklari engeller.
      if (soft_estop_latched)
      {
          final_left = 0.0f;
          final_right = 0.0f;
      }
      // Oncelik 2: Zaman asimina ugramamis Bluetooth manuel kontrolu.
      else if (left_target != 0 || right_target != 0)
      {
          final_left = left_target;
          final_right = right_target;
      }
      // Oncelik 3: OTONOM KONTROL (joystick birakildiysa Orange Pi sursun)
      else
      {
          final_left = opi_left_target;
          final_right = opi_right_target;
      }
      /* --------------------------------- */

      // Nihai hedefte degisiklik varsa motorlara ilet
      if ((final_left != prev_final_left) || (final_right != prev_final_right))
      {
          MotorControl_SetTargetRpm(final_left, final_right);
          prev_final_left = final_left;
          prev_final_right = final_right;
      }

      MotorControl_Process();
      BuzzerControl_Process();
      osDelay(1U);
  }
  /* USER CODE END 5 */
}

 /* MPU Configuration */

void MPU_Config(void)
{
  MPU_Region_InitTypeDef MPU_InitStruct = {0};

  /* Disables the MPU */
  HAL_MPU_Disable();

  /** Initializes and configures the Region and the memory to be protected
  */
  MPU_InitStruct.Enable = MPU_REGION_ENABLE;
  MPU_InitStruct.Number = MPU_REGION_NUMBER0;
  MPU_InitStruct.BaseAddress = 0x90000000;
  MPU_InitStruct.Size = MPU_REGION_SIZE_256MB;
  MPU_InitStruct.SubRegionDisable = 0x0;
  MPU_InitStruct.TypeExtField = MPU_TEX_LEVEL0;
  MPU_InitStruct.AccessPermission = MPU_REGION_FULL_ACCESS;
  MPU_InitStruct.DisableExec = MPU_INSTRUCTION_ACCESS_ENABLE;
  MPU_InitStruct.IsShareable = MPU_ACCESS_NOT_SHAREABLE;
  MPU_InitStruct.IsCacheable = MPU_ACCESS_NOT_CACHEABLE;
  MPU_InitStruct.IsBufferable = MPU_ACCESS_NOT_BUFFERABLE;

  HAL_MPU_ConfigRegion(&MPU_InitStruct);

  /** Initializes and configures the Region and the memory to be protected
  */
  MPU_InitStruct.Number = MPU_REGION_NUMBER1;
  MPU_InitStruct.Size = MPU_REGION_SIZE_16MB;
  MPU_InitStruct.IsCacheable = MPU_ACCESS_CACHEABLE;

  HAL_MPU_ConfigRegion(&MPU_InitStruct);
  /* Enables the MPU */
  HAL_MPU_Enable(MPU_PRIVILEGED_DEFAULT);

}

void HAL_TIM_PeriodElapsedCallback(TIM_HandleTypeDef *htim)
{
  if (htim->Instance == TIM6)
  {
    HAL_IncTick();
  }
}

void Error_Handler(void)
{
}
